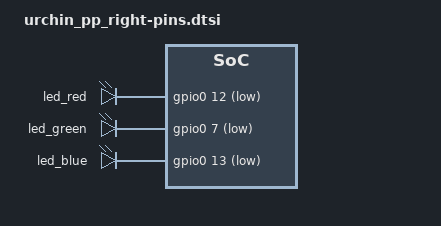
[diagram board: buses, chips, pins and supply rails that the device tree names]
/* Generated by scripts/firmware/gen_board.py from hardware/pinmap.json. Do not edit. */

&kscan0 {
    input-gpios
        = <&gpio0 31 (GPIO_ACTIVE_LOW | GPIO_PULL_UP)>  /* 0: r0c0 SW22, module pin 9 */
        , <&gpio1 13 (GPIO_ACTIVE_LOW | GPIO_PULL_UP)>  /* 1: r0c1 SW21, module pin 6 */
        , <&gpio0 3 (GPIO_ACTIVE_LOW | GPIO_PULL_UP)>  /* 2: r0c2 SW20, module pin 3 */
        , <&gpio1 10 (GPIO_ACTIVE_LOW | GPIO_PULL_UP)>  /* 3: r0c3 SW19, module pin 2 */
        , <&gpio1 11 (GPIO_ACTIVE_LOW | GPIO_PULL_UP)>  /* 4: r0c4 SW18, module pin 1 */
        , <&gpio0 0 (GPIO_ACTIVE_LOW | GPIO_PULL_UP)>  /* 5: r1c0 SW27, module pin 11 */
        , <&gpio0 30 (GPIO_ACTIVE_LOW | GPIO_PULL_UP)>  /* 6: r1c1 SW26, module pin 10 */
        , <&gpio0 2 (GPIO_ACTIVE_LOW | GPIO_PULL_UP)>  /* 7: r1c2 SW25, module pin 7 */
        , <&gpio0 29 (GPIO_ACTIVE_LOW | GPIO_PULL_UP)>  /* 8: r1c3 SW24, module pin 8 */
        , <&gpio0 28 (GPIO_ACTIVE_LOW | GPIO_PULL_UP)>  /* 9: r1c4 SW23, module pin 4 */
        , <&gpio0 5 (GPIO_ACTIVE_LOW | GPIO_PULL_UP)>  /* 10: r2c0 SW32, module pin 15 */
        , <&gpio0 1 (GPIO_ACTIVE_LOW | GPIO_PULL_UP)>  /* 11: r2c1 SW31, module pin 13 */
        , <&gpio0 26 (GPIO_ACTIVE_LOW | GPIO_PULL_UP)>  /* 12: r2c2 SW30, module pin 12 */
        , <&gpio0 6 (GPIO_ACTIVE_LOW | GPIO_PULL_UP)>  /* 13: r2c3 SW29, module pin 14 */
        , <&gpio0 8 (GPIO_ACTIVE_LOW | GPIO_PULL_UP)>  /* 14: r2c4 SW28, module pin 16 */
        , <&gpio1 9 (GPIO_ACTIVE_LOW | GPIO_PULL_UP)>  /* 15: t0 SW34, module pin 17 */
        , <&gpio0 4 (GPIO_ACTIVE_LOW | GPIO_PULL_UP)>  /* 16: t1 SW33, module pin 18 */
        ;
};

&led_red { gpios = <&gpio0 12 (GPIO_ACTIVE_LOW | GPIO_OPEN_DRAIN)>; };  /* status LED cathode, module pin 20 */
&led_green { gpios = <&gpio0 7 (GPIO_ACTIVE_LOW | GPIO_OPEN_DRAIN)>; };  /* status LED cathode, module pin 22 */
&led_blue { gpios = <&gpio0 13 (GPIO_ACTIVE_LOW | GPIO_OPEN_DRAIN)>; };  /* status LED cathode, module pin 33 */

&battery {
    power-good-gpios = <&gpio0 24 (GPIO_ACTIVE_LOW | GPIO_PULL_UP)>;  /* pgood_sense, module pin 35 */
    charging-gpios = <&gpio0 15 (GPIO_ACTIVE_LOW | GPIO_PULL_UP)>;  /* chg_sense, module pin 28 */
};

&default_transform {
    col-offset = <17>;
};
